VERSION ""

NS_ :

BS_:

BU_: BMS BRS ICU OBC TMS VCU

BO_ 352 VCU_BMS: 8 VCU
 SG_ VCU_PowerOnReq : 0|1@0+ (1,0) [0|1] ""  BMS
 SG_ VCU_UrgencyCutOffPowerReq : 1|1@0+ (1,0) [0|1] ""  BMS

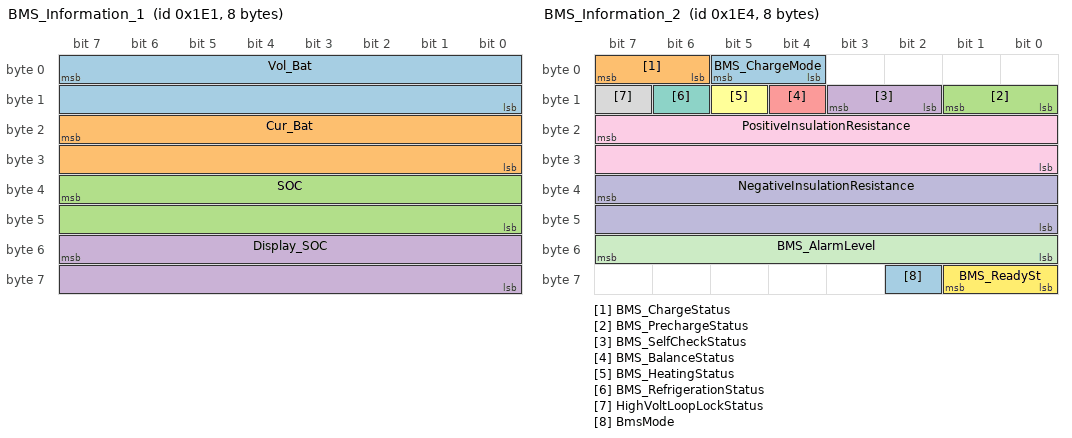
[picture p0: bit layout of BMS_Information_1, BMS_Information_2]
BO_ 481 BMS_Information_1: 8 BMS
 SG_ Vol_Bat : 7|16@0+ (0.1,0) [0|800] "V" Vector__XXX
 SG_ Cur_Bat : 23|16@0+ (0.1,-1000) [-1000|1000] "A" Vector__XXX
 SG_ SOC : 39|16@0+ (0.1,0) [0|100] "%"  VCU
 SG_ Display_SOC : 55|16@0+ (0.1,0) [0|100] "%"  ICU

BO_ 484 BMS_Information_2: 8 BMS
 SG_ BMS_ChargeMode : 5|2@0+ (1,0) [0|3] "" Vector__XXX
 SG_ BMS_ChargeStatus : 7|2@0+ (1,0) [0|3] "" Vector__XXX
 SG_ BMS_PrechargeStatus : 9|2@0+ (1,0) [0|3] "" Vector__XXX
 SG_ BMS_SelfCheckStatus : 11|2@0+ (1,0) [0|3] "" Vector__XXX
 SG_ BMS_BalanceStatus : 12|1@0+ (1,0) [0|1] "" Vector__XXX
 SG_ BMS_HeatingStatus : 13|1@0+ (1,0) [0|1] "" Vector__XXX
 SG_ BMS_RefrigerationStatus : 14|1@0+ (1,0) [0|1] "" Vector__XXX
 SG_ HighVoltLoopLockStatus : 15|1@0+ (1,0) [0|1] "" Vector__XXX
 SG_ PositiveInsulationResistance : 23|16@0+ (1,0) [0|60] "kohm" Vector__XXX
 SG_ NegativeInsulationResistance : 39|16@0+ (1,0) [0|60] "kohm" Vector__XXX
 SG_ BMS_AlarmLevel : 55|8@0+ (1,0) [0|15] "" Vector__XXX
 SG_ BMS_ReadySt : 57|2@0+ (1,0) [0|3] "" Vector__XXX
 SG_ BmsMode : 58|1@0+ (1,0) [0|1] "" Vector__XXX

BO_ 501 BMSWarning_Status: 8 BMS
 SG_ Alarm_Code : 7|8@0+ (1,0) [0|254] "" Vector__XXX
 SG_ Alarm_Level : 15|8@0+ (1,0) [0|255] "" Vector__XXX

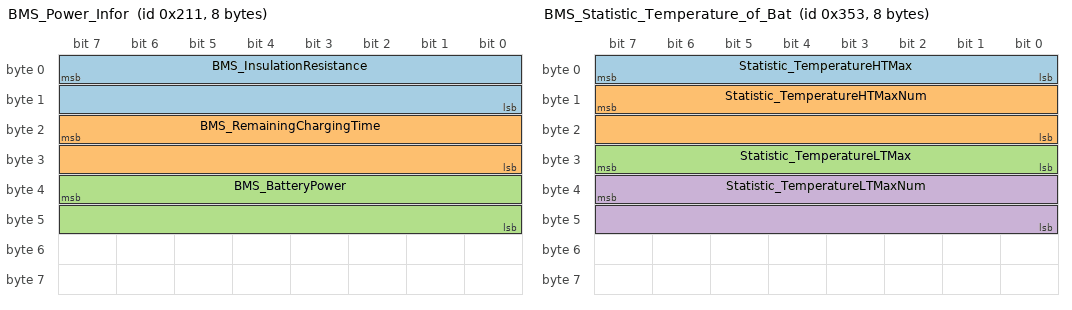
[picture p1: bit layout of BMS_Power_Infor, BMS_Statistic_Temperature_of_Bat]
BO_ 529 BMS_Power_Infor: 8 BMS
 SG_ BMS_InsulationResistance : 7|16@0+ (1,0) [0|60] "kΩ" Vector__XXX
 SG_ BMS_RemainingChargingTime : 23|16@0+ (1,0) [0|1800] "min" Vector__XXX
 SG_ BMS_BatteryPower : 39|16@0+ (0.01,-100) [-100|100] "kw" Vector__XXX

BO_ 851 BMS_Statistic_Temperature_of_Bat: 8 BMS
 SG_ Statistic_TemperatureHTMax : 7|8@0+ (1,-50) [-50|125] "℃" Vector__XXX
 SG_ Statistic_TemperatureHTMaxNum : 15|16@0+ (1,0) [1|1000] "" Vector__XXX
 SG_ Statistic_TemperatureLTMax : 31|8@0+ (1,-50) [-50|125] "℃" Vector__XXX
 SG_ Statistic_TemperatureLTMaxNum : 39|16@0+ (1,0) [1|1000] "" Vector__XXX

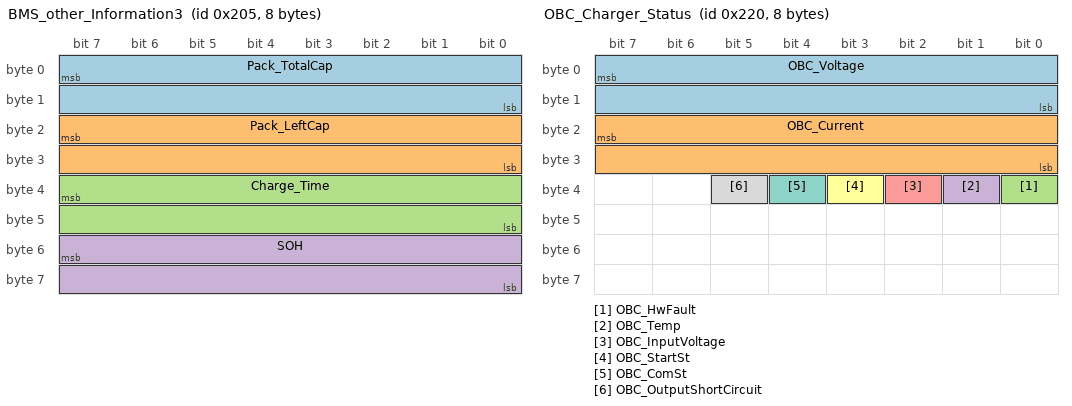
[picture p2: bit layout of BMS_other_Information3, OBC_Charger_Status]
BO_ 517 BMS_other_Information3: 8 BMS
 SG_ Pack_TotalCap : 7|16@0+ (0.1,0) [0|0] "AH" Vector__XXX
 SG_ Pack_LeftCap : 23|16@0+ (0.1,0) [0|0] "AH" Vector__XXX
 SG_ Charge_Time : 39|16@0+ (1,0) [0|6553.5] "min" Vector__XXX
 SG_ SOH : 55|16@0+ (0.1,0) [0|100] "%" Vector__XXX

BO_ 544 OBC_Charger_Status: 8 OBC
 SG_ OBC_Voltage : 7|16@0+ (0.1,0) [0|1000] "V" Vector__XXX
 SG_ OBC_Current : 23|16@0+ (0.1,0) [0|1000] "A" Vector__XXX
 SG_ OBC_HwFault : 32|1@0+ (1,0) [0|1] "" Vector__XXX
 SG_ OBC_Temp : 33|1@0+ (1,0) [0|1] "" Vector__XXX
 SG_ OBC_InputVoltage : 34|1@0+ (1,0) [0|1] "" Vector__XXX
 SG_ OBC_StartSt : 35|1@0+ (1,0) [0|1] "" Vector__XXX
 SG_ OBC_ComSt : 36|1@0+ (1,0) [0|1] "" Vector__XXX
 SG_ OBC_OutputShortCircuit : 37|1@0+ (1,0) [0|1] "" Vector__XXX

BO_ 2566910790 TMS2VCU: 8 Vector__XXX
 SG_ TMS_FanSpeedLvl_num : 7|8@0+ (1,0) [0|255] "" Vector__XXX
 SG_ TMS_Life1_num : 63|8@0+ (1,0) [0|255] "" Vector__XXX

BO_ 2566910791 VCU2TMS: 8 VCU
 SG_ VCU_FanSpeedLvl_num : 7|8@0+ (1,0) [0|255] "" Vector__XXX
 SG_ VCU_Life1_num : 63|8@0+ (1,0) [0|255] "" Vector__XXX

BO_ 2550212816 VCU2ICUInfor1: 8 VCU
 SG_ VCU_Pst_b : 0|1@1+ (1,0) [0|1] "" Vector__XXX
 SG_ VCU_SOCLoFlt_b : 1|1@1+ (1,0) [0|1] "" Vector__XXX
 SG_ VCU_RShift_b : 2|1@1+ (1,0) [0|1] "" Vector__XXX
 SG_ VCU_LShift_b : 3|1@1+ (1,0) [0|1] "" Vector__XXX
 SG_ VCU_EmrPumpSt_enum : 5|2@1+ (1,0) [0|3] "" Vector__XXX
 SG_ VCU_FltSt_enum : 6|1@1+ (1,0) [0|1] "" Vector__XXX
 SG_ VCU_WrkSt_enum : 7|1@1+ (1,0) [0|1] "" Vector__XXX
 SG_ VCU_VehSpd_kmh : 8|8@1+ (1,0) [0|255] "" Vector__XXX
 SG_ VCU_BattSOC_pct : 16|8@1+ (1,0) [0|100] "" Vector__XXX
 SG_ VCU_GearSt_enum : 24|8@1+ (1,0) [0|5] "" Vector__XXX
 SG_ VCU_BattTempHi_b : 32|1@1+ (1,0) [0|1] "" Vector__XXX
 SG_ VCU_HydSysFlt_b : 33|1@1+ (1,0) [0|1] "" Vector__XXX
 SG_ VCU_VehACharge_b : 34|1@1+ (1,0) [0|1] "" Vector__XXX
 SG_ VCU_MCUTempHiFlt_b : 35|1@1+ (1,0) [0|1] "" Vector__XXX
 SG_ VCU_MtTempHiFlt_b : 36|1@1+ (1,0) [0|1] "" Vector__XXX
 SG_ VCU_VehDCharge_b : 37|1@1+ (1,0) [0|1] "" Vector__XXX
 SG_ VCU_TopWrkSt_b : 38|1@1+ (1,0) [0|1] "" Vector__XXX
 SG_ VCU_BrakeFlt_b : 39|1@1+ (1,0) [0|1] "" Vector__XXX
 SG_ VCU_CoolSysFltIdc_b : 43|1@1+ (1,0) [0|1] "" Vector__XXX
 SG_ VCU_CoolFanWrkIdc_b : 44|1@1+ (1,0) [0|1] "" Vector__XXX
 SG_ VCU_RearLight_b : 45|1@1+ (1,0) [0|1] "" Vector__XXX
 SG_ VCU_HeadLight_b : 46|1@1+ (1,0) [0|1] "" Vector__XXX
 SG_ VCU_WatPumpOpenSt_b : 47|1@1+ (1,0) [0|1] "" Vector__XXX
 SG_ VCU_SysWorkStCode_num : 48|8@1+ (1,0) [0|255] "" Vector__XXX
 SG_ VCU_CoolSysFanPWM : 56|8@1+ (1,0) [0|100] "" Vector__XXX

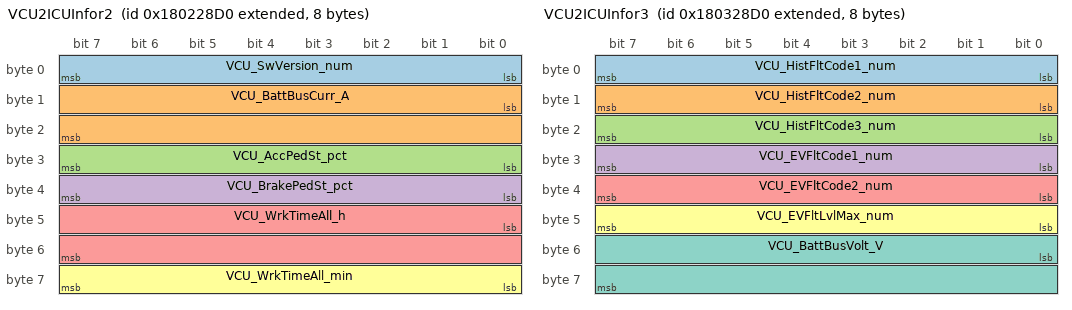
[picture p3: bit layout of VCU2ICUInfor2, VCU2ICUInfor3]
BO_ 2550278352 VCU2ICUInfor2: 8 VCU
 SG_ VCU_SwVersion_num : 0|8@1+ (0.1,0) [0|255] "" Vector__XXX
 SG_ VCU_BattBusCurr_A : 8|16@1- (0.1,-1000) [-1000|-1000] "" Vector__XXX
 SG_ VCU_AccPedSt_pct : 24|8@1+ (1,0) [0|100] "" Vector__XXX
 SG_ VCU_BrakePedSt_pct : 32|8@1+ (1,0) [0|100] "" Vector__XXX
 SG_ VCU_WrkTimeAll_h : 40|16@1+ (1,0) [0|65535] "" Vector__XXX
 SG_ VCU_WrkTimeAll_min : 56|8@1+ (1,0) [0|255] "" Vector__XXX

BO_ 2550343888 VCU2ICUInfor3: 8 VCU
 SG_ VCU_HistFltCode1_num : 0|8@1+ (1,0) [0|255] "" Vector__XXX
 SG_ VCU_HistFltCode2_num : 8|8@1+ (1,0) [0|255] "" Vector__XXX
 SG_ VCU_HistFltCode3_num : 16|8@1+ (1,0) [0|255] "" Vector__XXX
 SG_ VCU_EVFltCode1_num : 24|8@1+ (1,0) [0|255] "" Vector__XXX
 SG_ VCU_EVFltCode2_num : 32|8@1+ (1,0) [0|255] "" Vector__XXX
 SG_ VCU_EVFltLvlMax_num : 40|8@1+ (1,0) [0|3] "" Vector__XXX
 SG_ VCU_BattBusVolt_V : 48|16@1+ (0.1,0) [0|6553.5] "" Vector__XXX

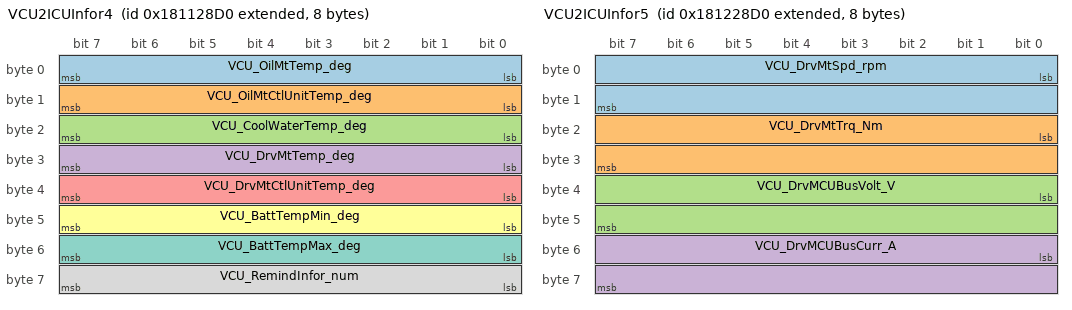
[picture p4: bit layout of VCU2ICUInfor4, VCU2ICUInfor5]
BO_ 2551261392 VCU2ICUInfor4: 8 VCU
 SG_ VCU_OilMtTemp_deg : 0|8@1- (1,-40) [-40|215] "" Vector__XXX
 SG_ VCU_OilMtCtlUnitTemp_deg : 8|8@1- (1,-40) [-40|215] "" Vector__XXX
 SG_ VCU_CoolWaterTemp_deg : 16|8@1- (1,-40) [-40|215] "" Vector__XXX
 SG_ VCU_DrvMtTemp_deg : 24|8@1- (1,-40) [-40|215] "" Vector__XXX
 SG_ VCU_DrvMtCtlUnitTemp_deg : 32|8@1- (1,-40) [-40|215] "" Vector__XXX
 SG_ VCU_BattTempMin_deg : 40|8@1- (1,-40) [-40|215] "" Vector__XXX
 SG_ VCU_BattTempMax_deg : 48|8@1- (1,-40) [-40|215] "" Vector__XXX
 SG_ VCU_RemindInfor_num : 56|8@1+ (1,0) [0|0] "" Vector__XXX

BO_ 2551326928 VCU2ICUInfor5: 8 VCU
 SG_ VCU_DrvMtSpd_rpm : 0|16@1- (1,-30000) [-30000|35535] "" Vector__XXX
 SG_ VCU_DrvMtTrq_Nm : 16|16@1+ (1,0) [0|65535] "" Vector__XXX
 SG_ VCU_DrvMCUBusVolt_V : 32|16@1+ (1,0) [0|65535] "" Vector__XXX
 SG_ VCU_DrvMCUBusCurr_A : 48|16@1- (1,-1000) [-1000|35535] "" Vector__XXX

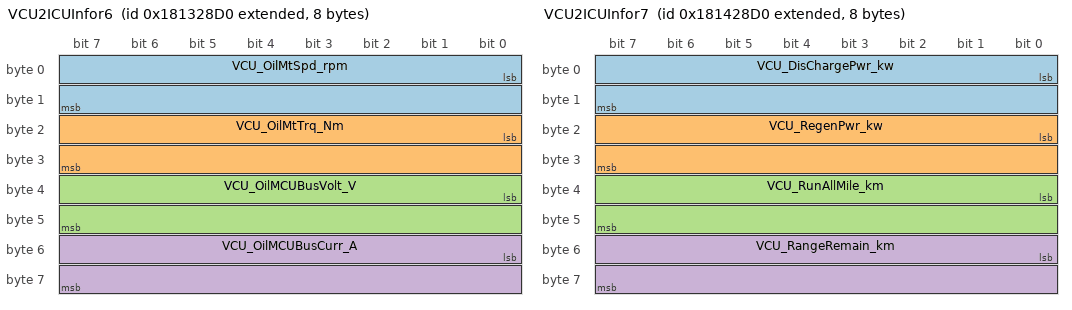
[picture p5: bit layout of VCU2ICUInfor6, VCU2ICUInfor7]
BO_ 2551392464 VCU2ICUInfor6: 8 VCU
 SG_ VCU_OilMtSpd_rpm : 0|16@1+ (1,0) [0|65535] "" Vector__XXX
 SG_ VCU_OilMtTrq_Nm : 16|16@1+ (1,0) [0|65535] "" Vector__XXX
 SG_ VCU_OilMCUBusVolt_V : 32|16@1+ (1,0) [0|65535] "" Vector__XXX
 SG_ VCU_OilMCUBusCurr_A : 48|16@1- (1,-1000) [-1000|35535] "" Vector__XXX

BO_ 2551458000 VCU2ICUInfor7: 8 VCU
 SG_ VCU_DisChargePwr_kw : 0|16@1+ (0.1,0) [0|10000] "" Vector__XXX
 SG_ VCU_RegenPwr_kw : 16|16@1+ (0.1,0) [0|10000] "" Vector__XXX
 SG_ VCU_RunAllMile_km : 32|16@1+ (1,0) [0|65535] "" Vector__XXX
 SG_ VCU_RangeRemain_km : 48|16@1+ (1,0) [0|65535] "" Vector__XXX

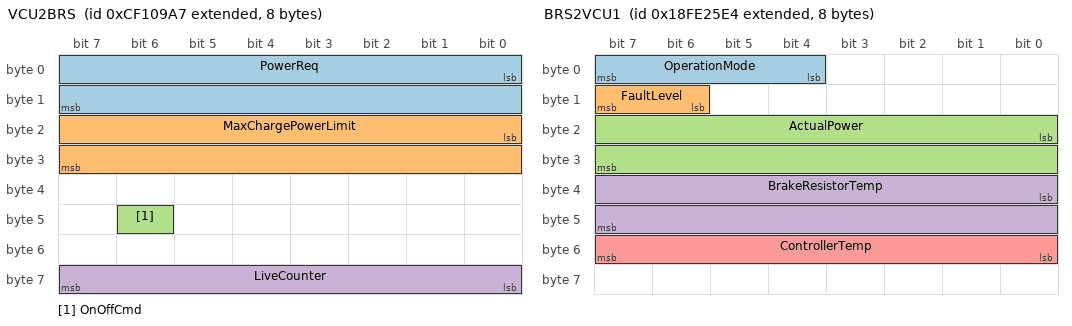
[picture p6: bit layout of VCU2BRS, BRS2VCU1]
BO_ 2364606887 VCU2BRS: 8 VCU
 SG_ PowerReq : 0|16@1+ (1,0) [0|500] "kW" Vector__XXX
 SG_ MaxChargePowerLimit : 16|16@1+ (1,0) [0|500] "kW" Vector__XXX
 SG_ OnOffCmd : 46|1@1+ (1,0) [0|1] "" Vector__XXX
 SG_ LiveCounter : 56|8@1+ (1,0) [0|255] "" Vector__XXX

BO_ 2566792676 BRS2VCU1: 8 Vector__XXX
 SG_ OperationMode : 4|4@1+ (1,0) [0|15] "" Vector__XXX
 SG_ FaultLevel : 14|2@1+ (1,0) [0|3] "" Vector__XXX
 SG_ ActualPower : 16|16@1+ (1,0) [0|500] "kW" Vector__XXX
 SG_ BrakeResistorTemp : 32|16@1+ (1,-40) [-40|470] "℃" Vector__XXX
 SG_ ControllerTemp : 48|8@1+ (1,-40) [-40|470] "℃" Vector__XXX

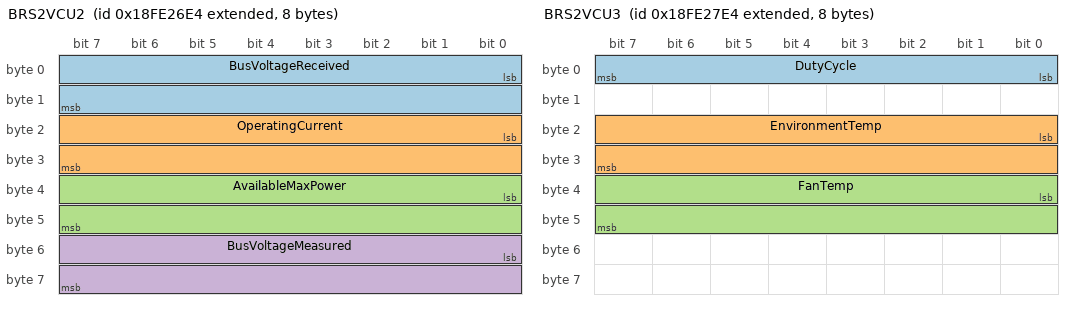
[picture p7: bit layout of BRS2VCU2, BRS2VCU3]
BO_ 2566792932 BRS2VCU2: 8 Vector__XXX
 SG_ BusVoltageReceived : 0|16@1+ (1,0) [0|1000] "V" Vector__XXX
 SG_ OperatingCurrent : 16|16@1+ (1,0) [0|1000] "A" Vector__XXX
 SG_ AvailableMaxPower : 32|16@1+ (1,0) [0|500] "kW" Vector__XXX
 SG_ BusVoltageMeasured : 48|16@1+ (0.1,0) [0|1000] "V" Vector__XXX

BO_ 2566793188 BRS2VCU3: 8 Vector__XXX
 SG_ DutyCycle : 0|8@1+ (1,0) [0|100] "%" Vector__XXX
 SG_ EnvironmentTemp : 16|16@1+ (1,-40) [-40|470] "℃" Vector__XXX
 SG_ FanTemp : 32|16@1+ (1,-40) [-40|470] "℃" Vector__XXX

CM_ SG_ 352 VCU_PowerOnReq "VCU高压上电命令; 0：请求下高压；; 1：请求上高压；";
CM_ SG_ 352 VCU_UrgencyCutOffPowerReq "VCU紧急下电命令; 0：未请求；; 1：请求下高压；";
CM_ SG_ 481 Vol_Bat "电池组总电压";
CM_ SG_ 481 Cur_Bat "电池组总电流";
CM_ SG_ 481 SOC "SOC";
CM_ SG_ 481 Display_SOC "SOC仪表显示; 总线数据≤0x32(50h)时，BMS一律处理为0（电量≤5%时，显示为0）";
CM_ SG_ 484 BMS_ChargeMode "BMS当前充电模式; 0：未充电; 1：直流模式; 2：交流模式; 3：保留";
CM_ SG_ 484 BMS_ChargeStatus "BMS当前充电状态; 0：未充电; 1：充电中; 2：充电完成; 3：保留";
CM_ SG_ 484 BMS_PrechargeStatus "BMS预充状态; 0：未预充; 1：预充中; 2：预充完成; 3：预充失败";
CM_ SG_ 484 BMS_SelfCheckStatus "BMS自检状态; 0：自检中; 1：自检完成; 2：自检失败; 3：保留";
CM_ SG_ 484 BMS_BalanceStatus "BMS均衡状态; 0：未均衡; 1：均衡中";
CM_ SG_ 484 BMS_HeatingStatus "BMS加热状态; 0：未加热; 1：加热中";
CM_ SG_ 484 BMS_RefrigerationStatus "BMS制冷状态; 0：未制冷; 1：制冷中";
CM_ SG_ 484 HighVoltLoopLockStatus "高压互锁状态; 0：未互锁; 1：互锁中";
CM_ SG_ 484 PositiveInsulationResistance "正极绝缘阻值";
CM_ SG_ 484 NegativeInsulationResistance "负极绝缘阻值";
CM_ SG_ 484 BMS_AlarmLevel "BMS最高报警等级; 0x00:无故障; 0x01:1级故障，不影响车辆正常行驶; 0x02:2级故障，影像车辆性能，需要驾驶员限制行驶; 0x03:3级故障，应立即停车处理或请求救援; 0x04:4级故障，最高级别，应立即停车处理或请求救援; 0xFE:异常; 0xFF:无效";
CM_ SG_ 484 BMS_ReadySt "BMS上电Ready信号; 0：Not Ready; 1：Ready; 2：Error; 3：Reserve";
CM_ SG_ 484 BmsMode "BMS主从模式; 0：一体机模式; 1：主从模式";
CM_ SG_ 501 Alarm_Code "报警码; 见故障码定义";
CM_ SG_ 501 Alarm_Level "报警等级; 0x00:无故障; 0x01:1级故障; 0x02:2级故障; 0x03:3级故障; 0x04:4级故障; 0xFE:异常; 0xFF:无效";
CM_ SG_ 529 BMS_InsulationResistance "绝缘电阻";
CM_ SG_ 529 BMS_RemainingChargingTime "剩余充电时间";
CM_ SG_ 529 BMS_BatteryPower "电池功率,正功率表示对电池充电，负功率表示电池放电。";
CM_ SG_ 851 Statistic_TemperatureHTMax "电池最高温度";
CM_ SG_ 851 Statistic_TemperatureHTMaxNum "电池最高温度编号";
CM_ SG_ 851 Statistic_TemperatureLTMax "电池最低温度";
CM_ SG_ 851 Statistic_TemperatureLTMaxNum "电池最低温度编号";
CM_ SG_ 517 Pack_TotalCap "电池总容量";
CM_ SG_ 517 Pack_LeftCap "电池组剩余容量";
CM_ SG_ 517 Charge_Time "已充电时间";
CM_ SG_ 517 SOH "SOH";
CM_ SG_ 544 OBC_Voltage "当前充电电压";
CM_ SG_ 544 OBC_Current "当前充电电流";
CM_ SG_ 544 OBC_HwFault "硬件故障; 0：正常；; 1：硬件故障；";
CM_ SG_ 544 OBC_Temp "充电机温度; 0：正常；; 1：充电机温度过高保护；";
CM_ SG_ 544 OBC_InputVoltage "输入电压; 0：正常；; 1：输入电压错误，充电机停止工作；";
CM_ SG_ 544 OBC_StartSt "启动状态; 0：电池电压正常，可以启动；; 1：电池电压异常，不允许启动；";
CM_ SG_ 544 OBC_ComSt "通信状态; 0：通讯正常；; 1：通讯指令超时或者是收到指令异常；";
CM_ SG_ 544 OBC_OutputShortCircuit "输出短路; 0：正常；; 1：输出过流、短路，充电机停止工作；";
CM_ SG_ 2566910790 TMS_FanSpeedLvl_num "风机档位";
CM_ SG_ 2566910790 TMS_Life1_num "Life";
CM_ SG_ 2566910791 VCU_FanSpeedLvl_num "风机档位";
CM_ SG_ 2566910791 VCU_Life1_num "Life";
CM_ SG_ 2550212816 VCU_Pst_b "驻车制动";
CM_ SG_ 2550212816 VCU_SOCLoFlt_b "SOC低报警";
CM_ SG_ 2550212816 VCU_RShift_b "右转向";
CM_ SG_ 2550212816 VCU_LShift_b "左转向";
CM_ SG_ 2550212816 VCU_EmrPumpSt_enum "紧急泵送状态";
CM_ SG_ 2550212816 VCU_FltSt_enum "底盘故障状态";
CM_ SG_ 2550212816 VCU_WrkSt_enum "底盘运行状态";
CM_ SG_ 2550212816 VCU_VehSpd_kmh "车辆速度";
CM_ SG_ 2550212816 VCU_BattSOC_pct "电池SOC";
CM_ SG_ 2550212816 VCU_GearSt_enum "档位状态";
CM_ SG_ 2550212816 VCU_BattTempHi_b "动力电池过温";
CM_ SG_ 2550212816 VCU_HydSysFlt_b "液压系统故障";
CM_ SG_ 2550212816 VCU_VehACharge_b "整机慢充";
CM_ SG_ 2550212816 VCU_MCUTempHiFlt_b "电控过温报警";
CM_ SG_ 2550212816 VCU_MtTempHiFlt_b "电机过温报警";
CM_ SG_ 2550212816 VCU_VehDCharge_b "整机快充";
CM_ SG_ 2550212816 VCU_TopWrkSt_b "上装工作状态";
CM_ SG_ 2550212816 VCU_BrakeFlt_b "制动故障";
CM_ SG_ 2550212816 VCU_CoolSysFltIdc_b "散热系统故障指示";
CM_ SG_ 2550212816 VCU_CoolFanWrkIdc_b "散热风扇工作指示";
CM_ SG_ 2550212816 VCU_RearLight_b "后照灯";
CM_ SG_ 2550212816 VCU_HeadLight_b "前照灯";
CM_ SG_ 2550212816 VCU_WatPumpOpenSt_b "水泵开启状态";
CM_ SG_ 2550212816 VCU_SysWorkStCode_num "VCU运行状态码";
CM_ SG_ 2550212816 VCU_CoolSysFanPWM "散热风扇控制PWM";
CM_ SG_ 2550278352 VCU_SwVersion_num "VCU版本信息";
CM_ SG_ 2550278352 VCU_BattBusCurr_A "电池母线电流";
CM_ SG_ 2550278352 VCU_AccPedSt_pct "油门踏板状态";
CM_ SG_ 2550278352 VCU_BrakePedSt_pct "制动踏板状态";
CM_ SG_ 2550278352 VCU_WrkTimeAll_h "运行总时间（h）";
CM_ SG_ 2550278352 VCU_WrkTimeAll_min "运行总时间（min）";
CM_ SG_ 2550343888 VCU_HistFltCode1_num "历史故障代码1";
CM_ SG_ 2550343888 VCU_HistFltCode2_num "历史故障代码2";
CM_ SG_ 2550343888 VCU_HistFltCode3_num "历史故障代码3";
CM_ SG_ 2550343888 VCU_EVFltCode1_num "整车当前故障代码1";
CM_ SG_ 2550343888 VCU_EVFltCode2_num "整车当前故障代码2";
CM_ SG_ 2550343888 VCU_EVFltLvlMax_num "整车当前最高故障等级";
CM_ SG_ 2550343888 VCU_BattBusVolt_V "电池母线电压";
CM_ SG_ 2551261392 VCU_OilMtTemp_deg "油泵电机温度";
CM_ SG_ 2551261392 VCU_OilMtCtlUnitTemp_deg "油泵电机控制器温度";
CM_ SG_ 2551261392 VCU_CoolWaterTemp_deg "散热水温度";
CM_ SG_ 2551261392 VCU_DrvMtTemp_deg "驱动电机温度";
CM_ SG_ 2551261392 VCU_DrvMtCtlUnitTemp_deg "驱动电机控制器温度";
CM_ SG_ 2551261392 VCU_BattTempMin_deg "电池最低温度";
CM_ SG_ 2551261392 VCU_BattTempMax_deg "电池最高温度";
CM_ SG_ 2551261392 VCU_RemindInfor_num "提示信息";
CM_ SG_ 2551326928 VCU_DrvMtSpd_rpm "驱动电机转速";
CM_ SG_ 2551326928 VCU_DrvMtTrq_Nm "驱动电机转矩";
CM_ SG_ 2551326928 VCU_DrvMCUBusVolt_V "驱动电机控制器母线电压";
CM_ SG_ 2551326928 VCU_DrvMCUBusCurr_A "驱动电机控制器母线电流";
CM_ SG_ 2551392464 VCU_OilMtSpd_rpm "油泵电机转速";
CM_ SG_ 2551392464 VCU_OilMtTrq_Nm "油泵电机转矩";
CM_ SG_ 2551392464 VCU_OilMCUBusVolt_V "油泵电机控制器母线电压";
CM_ SG_ 2551392464 VCU_OilMCUBusCurr_A "油泵电机控制器母线电流";
CM_ SG_ 2551458000 VCU_DisChargePwr_kw "电池放电功率";
CM_ SG_ 2551458000 VCU_RegenPwr_kw "能量回收功率";
CM_ SG_ 2551458000 VCU_RunAllMile_km "行驶总里程";
CM_ SG_ 2551458000 VCU_RangeRemain_km "剩余续航里程";
CM_ SG_ 2364606887 PowerReq "请求制动电阻器消耗的功率";
CM_ SG_ 2364606887 MaxChargePowerLimit "动力电池最大允许充电功率";
CM_ SG_ 2364606887 OnOffCmd "制动电阻器上下电指令; 0 = 请求下高压; 1 =请求上高压";
CM_ SG_ 2364606887 LiveCounter "整车控制器life";
CM_ SG_ 2566792676 OperationMode "工作模式; 0x1：工作 ; 0x2：全直通工作; 0x3：待机(制动电阻控制器接触器吸合）; 0x6：停机(制动电阻控制器接触器断开）";
CM_ SG_ 2566792676 FaultLevel "故障等级; 0x0：无故障; 0x1：一级故障; 0x2：二级故障; 0x3：无效";
CM_ SG_ 2566792676 ActualPower "实际功率";
CM_ SG_ 2566792676 BrakeResistorTemp "制动电阻温度";
CM_ SG_ 2566792676 ControllerTemp "控制器温度";
CM_ SG_ 2566792932 BusVoltageReceived "接收到的母线电压";
CM_ SG_ 2566792932 OperatingCurrent "工作电流";
CM_ SG_ 2566792932 AvailableMaxPower "当前可执行最大功率";
CM_ SG_ 2566792932 BusVoltageMeasured "采集到的母线电压";
CM_ SG_ 2566793188 DutyCycle "工作占空比";
CM_ SG_ 2566793188 EnvironmentTemp "环境温度";
CM_ SG_ 2566793188 FanTemp "风扇端温度值";
BA_DEF_ BO_  "GenMsgCycleTime" INT 0 60000;
BA_DEF_ BO_  "VFrameFormat" ENUM  "StandardCAN","ExtendedCAN","reserved","J1939PG";
BA_DEF_DEF_  "GenMsgCycleTime" 0;
BA_DEF_DEF_  "VFrameFormat" "ExtendedCAN";
BA_ "VFrameFormat" BO_ 352 0;
BA_ "GenMsgCycleTime" BO_ 352 100;
BA_ "VFrameFormat" BO_ 481 0;
BA_ "GenMsgCycleTime" BO_ 481 100;
BA_ "VFrameFormat" BO_ 484 0;
BA_ "GenMsgCycleTime" BO_ 484 100;
BA_ "VFrameFormat" BO_ 501 0;
BA_ "GenMsgCycleTime" BO_ 501 100;
BA_ "VFrameFormat" BO_ 529 0;
BA_ "GenMsgCycleTime" BO_ 529 500;
BA_ "VFrameFormat" BO_ 851 0;
BA_ "GenMsgCycleTime" BO_ 851 200;
BA_ "VFrameFormat" BO_ 517 0;
BA_ "GenMsgCycleTime" BO_ 517 1000;
BA_ "VFrameFormat" BO_ 544 0;
BA_ "GenMsgCycleTime" BO_ 544 500;
BA_ "GenMsgCycleTime" BO_ 2566910790 500;
BA_ "GenMsgCycleTime" BO_ 2566910791 500;
BA_ "GenMsgCycleTime" BO_ 2550212816 100;
BA_ "GenMsgCycleTime" BO_ 2550278352 200;
BA_ "GenMsgCycleTime" BO_ 2550343888 100;
BA_ "GenMsgCycleTime" BO_ 2551261392 100;
BA_ "GenMsgCycleTime" BO_ 2551326928 100;
BA_ "GenMsgCycleTime" BO_ 2551392464 100;
BA_ "GenMsgCycleTime" BO_ 2551458000 100;
BA_ "GenMsgCycleTime" BO_ 2364606887 100;
BA_ "GenMsgCycleTime" BO_ 2566792676 500;
BA_ "GenMsgCycleTime" BO_ 2566792932 500;
BA_ "GenMsgCycleTime" BO_ 2566793188 500;
VAL_ 352 VCU_PowerOnReq 0 "请求下高压" 1 "请求上高压" ;
VAL_ 352 VCU_UrgencyCutOffPowerReq 0 "未请求" 1 "请求下高压" ;
VAL_ 484 BMS_ChargeMode 0 "未充电" 1 "直流模式" 2 "交流模式" 3 "保留" ;
VAL_ 484 BMS_ChargeStatus 0 "未充电" 1 "充电中" 2 "充电完成" 3 "保留" ;
VAL_ 484 BMS_PrechargeStatus 0 "未预充" 1 "预充中" 2 "预充完成" 3 "预充失败" ;
VAL_ 484 BMS_SelfCheckStatus 0 "自检中" 1 "自检完成" 2 "自检失败" 3 "保留" ;
VAL_ 484 BMS_BalanceStatus 0 "未均衡" 1 "均衡中" ;
VAL_ 484 BMS_HeatingStatus 0 "未加热" 1 "加热中" ;
VAL_ 484 BMS_RefrigerationStatus 0 "未制冷" 1 "制冷中" ;
VAL_ 484 HighVoltLoopLockStatus 0 "未互锁" 1 "互锁中" ;
VAL_ 484 BMS_AlarmLevel 0 "无故障" 1 "1级故障，不影响车辆正常行驶" 2 "2级故障，影像车辆性能，需要驾驶员限制行驶" 3 "3级故障，应立即停车处理或请求救援" 4 "4级故障，最高级别，应立即停车处理或请求救援" 254 "异常" 255 "无效" ;
VAL_ 484 BMS_ReadySt 0 "Not Ready" 1 "Ready" 2 "Error" 3 "Reserve" ;
VAL_ 484 BmsMode 0 "一体机模式" 1 "主从模式" ;
VAL_ 501 Alarm_Level 0 "无故障" 1 "1级故障" 2 "2级故障" 3 "3级故障" 4 "4级故障" 254 "异常" 255 "无效" ;
VAL_ 544 OBC_HwFault 0 "正常" 1 "硬件故障" ;
VAL_ 544 OBC_Temp 0 "正常" 1 "充电机温度过高保护" ;
VAL_ 544 OBC_InputVoltage 0 "正常" 1 "输入电压错误，充电机停止工作" ;
VAL_ 544 OBC_StartSt 0 "电池电压正常，可以启动" 1 "电池电压异常，不允许启动" ;
VAL_ 544 OBC_ComSt 0 "通讯正常" 1 "通讯指令超时或者是收到指令异常" ;
VAL_ 544 OBC_OutputShortCircuit 0 "正常" 1 "输出过流、短路，充电机停止工作" ;
VAL_ 2364606887 OnOffCmd 0 "请求下高压" 1 "请求上高压" ;
VAL_ 2566792676 OperationMode 1 "工作" 2 "全直通工作" 3 "待机(制动电阻控制器接触器吸合）" 6 "停机(制动电阻控制器接触器断开）" ;
VAL_ 2566792676 FaultLevel 0 "无故障" 1 "一级故障" 2 "二级故障" 3 "无效" ;
